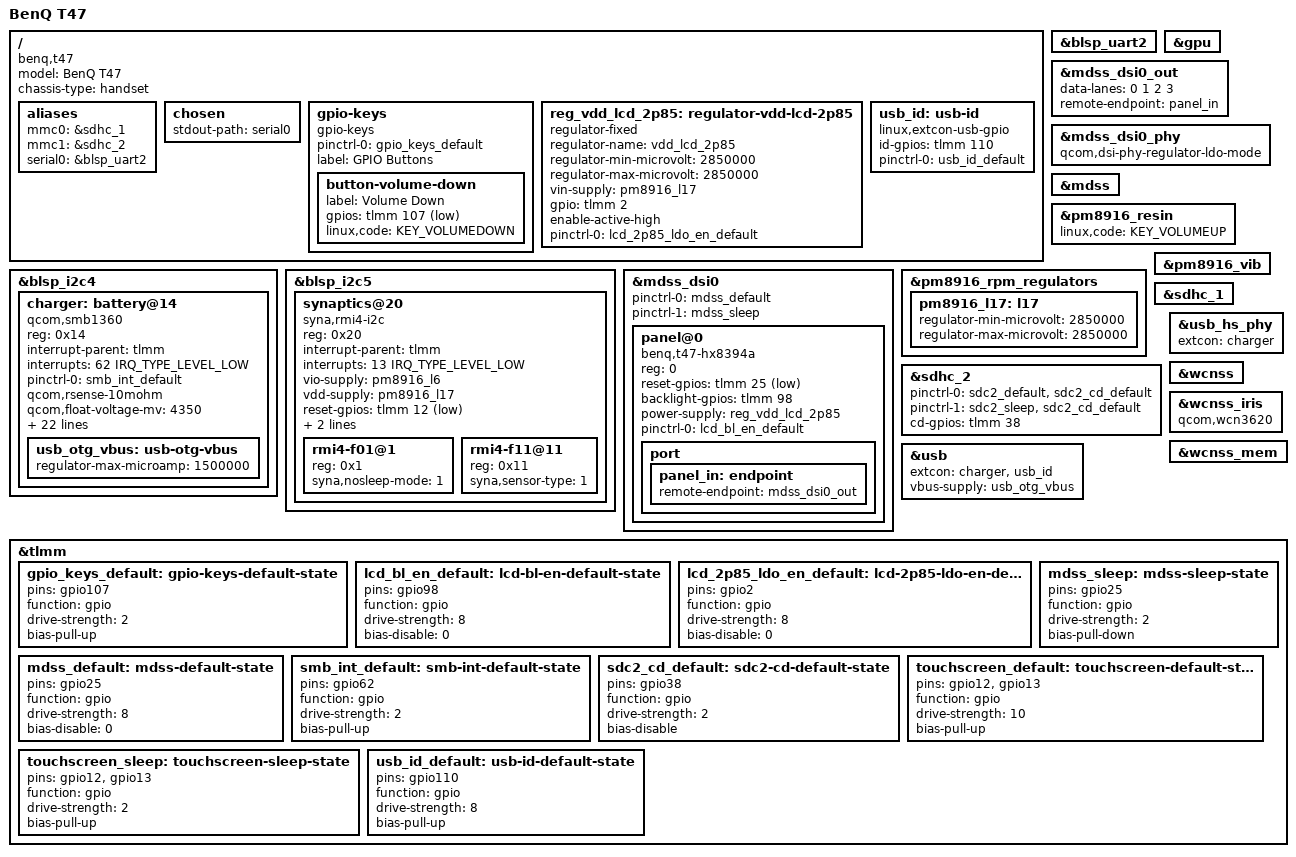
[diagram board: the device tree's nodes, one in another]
// SPDX-License-Identifier: GPL-2.0-only

/dts-v1/;

#include "msm8916-pm8916.dtsi"

#include <dt-bindings/gpio/gpio.h>

/ {
 	model = "BenQ T47"; 
 	compatible = "benq,t47", "qcom,msm8916";
	chassis-type = "handset";

	aliases {
		mmc0 = &sdhc_1; /* eMMC */
		mmc1 = &sdhc_2; /* SD card */
		serial0 = &blsp_uart2;
	};

	chosen {
		stdout-path = "serial0";
	};

	gpio-keys {
		compatible = "gpio-keys";

		pinctrl-0 = <&gpio_keys_default>;
		pinctrl-names = "default";

		label = "GPIO Buttons";

		button-volume-down {
			label = "Volume Down";
			gpios = <&tlmm 107 GPIO_ACTIVE_LOW>;
			linux,code = <KEY_VOLUMEDOWN>;
		};
	};

	reg_vdd_lcd_2p85: regulator-vdd-lcd-2p85 {
		compatible = "regulator-fixed";
		regulator-name = "vdd_lcd_2p85";
		regulator-min-microvolt = <2850000>;
		regulator-max-microvolt = <2850000>;
		vin-supply = <&pm8916_l17>;
		gpio = <&tlmm 2 GPIO_ACTIVE_HIGH>;
		enable-active-high;
		pinctrl-0 = <&lcd_2p85_ldo_en_default>;
		pinctrl-names = "default";
	};

	usb_id: usb-id {
		compatible = "linux,extcon-usb-gpio";
		id-gpios = <&tlmm 110 GPIO_ACTIVE_HIGH>;
		pinctrl-0 = <&usb_id_default>;
		pinctrl-names = "default";
	};
};

&blsp_i2c4 {
	status = "okay";

	charger: battery@14 {
		compatible = "qcom,smb1360";
		reg = <0x14>;

		interrupt-parent = <&tlmm>;
		interrupts = <62 IRQ_TYPE_LEVEL_LOW>;

		pinctrl-names = "default";
		pinctrl-0 = <&smb_int_default>;

		qcom,rsense-10mohm;

		qcom,float-voltage-mv = <4350>;
		qcom,iterm-ma = <100>;
		qcom,charging-timeout = <1536>;
		qcom,recharge-thresh-mv = <100>;
		qcom,chg-inhibit-disabled;

		qcom,fg-batt-capacity-mah = <2080>;
		qcom,fg-cc-soc-coeff = <0x880D>;
		qcom,fg-cutoff-voltage-mv = <3400>;
		qcom,fg-iterm-ma = <100>;
		qcom,fg-cc-to-cv-mv = <4328>;
		qcom,thermistor-c1-coeff = <0x86DA>;
		qcom,fg-auto-recharge-soc = <95>;

		qcom,otp-hard-jeita-config;
		qcom,otp-hot-bat-decidegc = <540>;
		qcom,otp-cold-bat-decidegc = <0>;

		qcom,soft-jeita-config;
		qcom,warm-bat-decidegc = <450>;
		qcom,cool-bat-decidegc = <150>;
		qcom,soft-jeita-comp-voltage-mv = <4250>;
		qcom,soft-jeita-comp-current-ma = <450>;

		qcom,shdn-after-pwroff;
		qcom,fg-reset-at-pon;
		qcom,fg-reset-thresold-mv = <250>;

		usb_otg_vbus: usb-otg-vbus {
			regulator-max-microamp = <1500000>;
		};
	};
};

&blsp_i2c5 {
	status = "okay";

	synaptics@20 {
		compatible = "syna,rmi4-i2c";
		reg = <0x20>;
		#address-cells = <1>;
		#size-cells = <0>;
		interrupt-parent = <&tlmm>;
		interrupts = <13 IRQ_TYPE_LEVEL_LOW>;
		vio-supply = <&pm8916_l6>;
		vdd-supply = <&pm8916_l17>;
		reset-gpios = <&tlmm 12 GPIO_ACTIVE_LOW>;
		pinctrl-names = "default", "sleep";
		pinctrl-0 = <&touchscreen_default>;
		pinctrl-1 = <&touchscreen_sleep>;

		rmi4-f01@1 {
			reg = <0x1>;
			syna,nosleep-mode = <1>;
		};

		rmi4-f11@11 {
			reg = <0x11>;
			syna,sensor-type = <1>;
		};
	};
};

&blsp_uart2 {
	status = "okay";
};

&gpu {
	status = "okay";
};

&mdss_dsi0 {
	pinctrl-names = "default", "sleep";
	pinctrl-0 = <&mdss_default>;
	pinctrl-1 = <&mdss_sleep>;

	panel@0 {
		compatible = "benq,t47-hx8394a";
		reg = <0>;

		reset-gpios = <&tlmm 25 GPIO_ACTIVE_LOW>;
		backlight-gpios = <&tlmm 98 GPIO_ACTIVE_HIGH>;
		power-supply = <&reg_vdd_lcd_2p85>;

		pinctrl-names = "default";
		pinctrl-0 = <&lcd_bl_en_default>;

		port {
			panel_in: endpoint {
				remote-endpoint = <&mdss_dsi0_out>;
			};
		};
	};
};

&mdss_dsi0_out {
	data-lanes = <0 1 2 3>;
	remote-endpoint = <&panel_in>;
};

&mdss_dsi0_phy {
	qcom,dsi-phy-regulator-ldo-mode;
};

&mdss {
	status = "okay";
};

&pm8916_resin {
	linux,code = <KEY_VOLUMEUP>;
	status = "okay";
};

&pm8916_rpm_regulators {
	pm8916_l17: l17 {
		regulator-min-microvolt = <2850000>;
		regulator-max-microvolt = <2850000>;
	};
};

&pm8916_vib {
	status = "okay";
};

&sdhc_1 {
	status = "okay";
};

&sdhc_2 {
	pinctrl-0 = <&sdc2_default &sdc2_cd_default>;
	pinctrl-1 = <&sdc2_sleep &sdc2_cd_default>;
	pinctrl-names = "default", "sleep";

	cd-gpios = <&tlmm 38 GPIO_ACTIVE_HIGH>;

	status = "okay";
};

&usb {
	status = "okay";
	extcon = <&charger>, <&usb_id>;
	vbus-supply = <&usb_otg_vbus>;
};

&usb_hs_phy {
	extcon = <&charger>;
};

&wcnss {
	status = "okay";
};

&wcnss_iris {
	compatible = "qcom,wcn3620";
};

&wcnss_mem {
	status = "okay";
};

&tlmm {
	gpio_keys_default: gpio-keys-default-state {
		pins = "gpio107";
		function = "gpio";
		drive-strength = <2>;
		bias-pull-up;
	};

	lcd_bl_en_default: lcd-bl-en-default-state {
		pins = "gpio98";
		function = "gpio";
		drive-strength = <8>;
		bias-disable = <0>;
	};

	lcd_2p85_ldo_en_default: lcd-2p85-ldo-en-default-state {
		pins = "gpio2";
		function = "gpio";
		drive-strength = <8>;
		bias-disable = <0>;
	};

	mdss_default: mdss-default-state {
		pins = "gpio25";
		function = "gpio";
		drive-strength = <8>;
		bias-disable = <0>;
	};

	mdss_sleep: mdss-sleep-state {
		pins = "gpio25";
		function = "gpio";
		drive-strength = <2>;
		bias-pull-down;
	};

	smb_int_default: smb-int-default-state {
		pins = "gpio62";
		function = "gpio";
		drive-strength = <2>;
		bias-pull-up;
	};	

	sdc2_cd_default: sdc2-cd-default-state {
		pins = "gpio38";
		function = "gpio";
		drive-strength = <2>;
		bias-disable;
	};

	touchscreen_default: touchscreen-default-state {
		pins = "gpio12", "gpio13";
		function = "gpio";
		drive-strength = <10>;
		bias-pull-up;
	};

	touchscreen_sleep: touchscreen-sleep-state {
		pins = "gpio12", "gpio13";
		function = "gpio";
		drive-strength = <2>;
		bias-pull-up;
	};

	usb_id_default: usb-id-default-state {
		pins = "gpio110";
		function = "gpio";
		drive-strength = <8>;
		bias-pull-up;
	};
};
